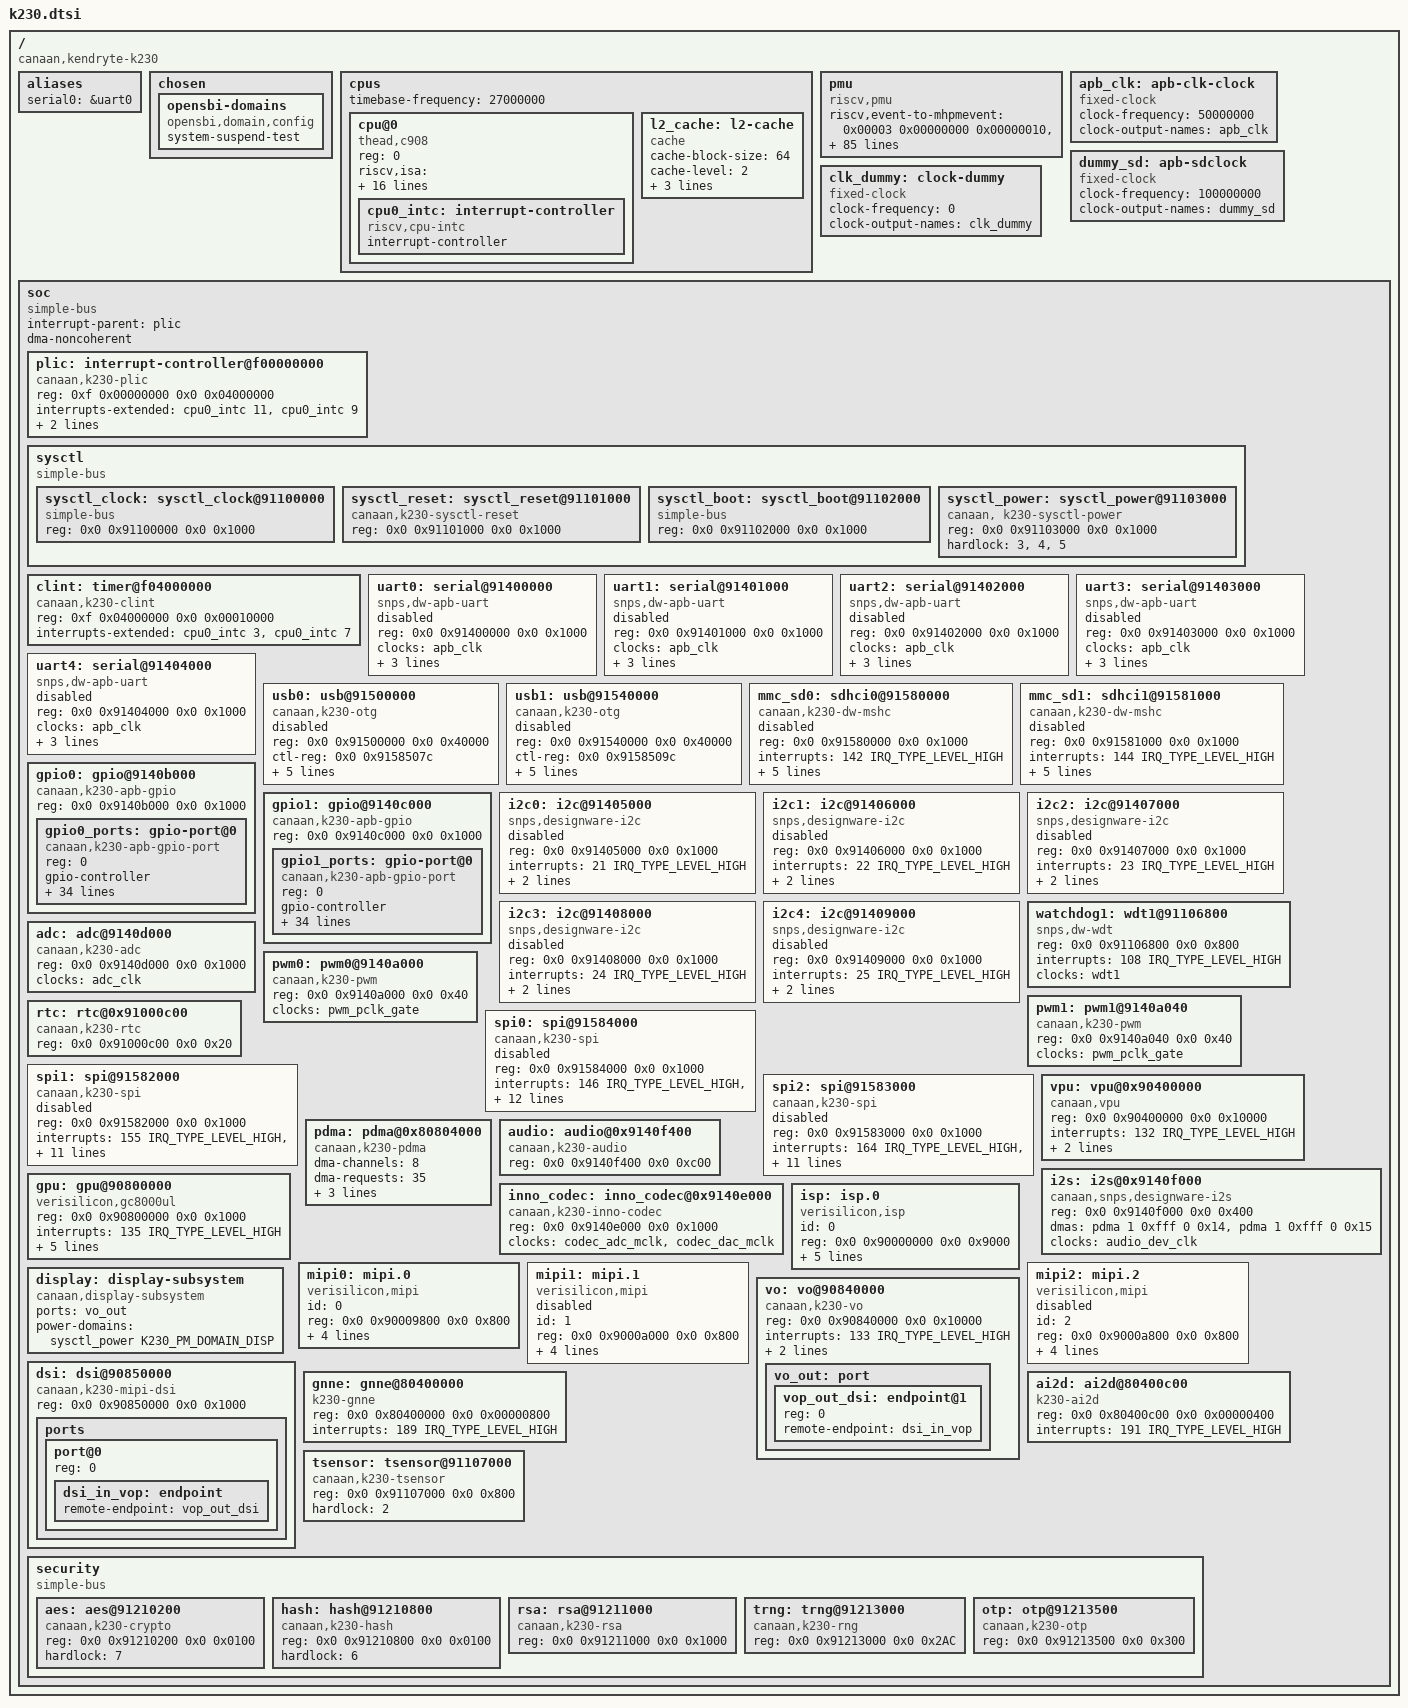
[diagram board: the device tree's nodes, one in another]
// SPDX-License-Identifier: GPL-2.0 OR MIT
/*
 * Copyright (C) 2024 Yangyu Chen <cyy@cyyself.name>
 */

#include <dt-bindings/interrupt-controller/irq.h>
#include <dt-bindings/soc/canaan,k230_pm_domains.h>
#include <dt-bindings/reset/canaan-k230-reset.h>
#include <dt-bindings/gpio/gpio.h>

/dts-v1/;
/ {
	#address-cells = <2>;
	#size-cells = <2>;
	compatible = "canaan,kendryte-k230";

	aliases {
		serial0 = &uart0;
	};

	chosen {
		opensbi-domains {
			compatible = "opensbi,domain,config";
			system-suspend-test;
		};
	};

	cpus {
		#address-cells = <1>;
		#size-cells = <0>;
		timebase-frequency = <27000000>;

		cpu@0 {
			compatible = "thead,c908", "riscv";
			device_type = "cpu";
			reg = <0>;
			riscv,isa = "rv64imafdcv_zba_zbb_zbc_zbs_zicbom_zicbop_zicboz_svpbmt";
			riscv,isa-base = "rv64i";
			riscv,isa-extensions = "i", "m", "a", "f", "d", "c", "v", "zba", "zbb",
					       "zbc", "zbs", "zicbom", "zicbop", "zicboz",
					       "zicntr", "zicsr", "zifencei", "zihpm", "svpbmt";
			riscv,cbom-block-size = <64>;
			riscv,cbop-block-size = <64>;
			riscv,cboz-block-size = <64>;
			d-cache-block-size = <64>;
			d-cache-sets = <128>;
			d-cache-size = <32768>;
			i-cache-block-size = <64>;
			i-cache-sets = <128>;
			i-cache-size = <32768>;
			next-level-cache = <&l2_cache>;
			mmu-type = "riscv,sv39";

			cpu0_intc: interrupt-controller {
				compatible = "riscv,cpu-intc";
				interrupt-controller;
				#interrupt-cells = <1>;
			};
		};

		l2_cache: l2-cache {
			compatible = "cache";
			cache-block-size = <64>;
			cache-level = <2>;
			cache-size = <262144>;
			cache-sets = <256>;
			cache-unified;
		};
	};

	pmu {
		compatible = "riscv,pmu";
		riscv,event-to-mhpmevent =
			/* PMU_HW_CACHE_REFERENCES -> ll_cache_read_access */
			<0x00003 0x00000000 0x00000010>,
			/* PMU_HW_CACHE_MISSES -> ll_cache_read_miss */
			<0x00004 0x00000000 0x00000011>,
			/* PMU_HW_BRANCH_INSTRUCTIONS -> inst_branch */
			<0x00005 0x00000000 0x00000007>,
			/* PMU_HW_BRANCH_MISSES -> inst_branch_mispredict */
			<0x00006 0x00000000 0x00000006>,
			/* PMU_HW_STALLED_CYCLES_FRONTEND -> ifu_stalled_cycle */
			<0x00008 0x00000000 0x00000027>,
			/* PMU_HW_STALLED_CYCLES_BACKEND -> idu_stalled_cycle */
			<0x00009 0x00000000 0x00000028>,
			/* L1D_READ_ACCESS -> l1_dcache_read_access */
			<0x10000 0x00000000 0x0000000c>,
			/* L1D_READ_MISS -> l1_dcache_read_miss */
			<0x10001 0x00000000 0x0000000d>,
			/* L1D_WRITE_ACCESS -> l1_dcache_write_access */
			<0x10002 0x00000000 0x0000000e>,
			/* L1D_WRITE_MISS -> l1_dcache_write_miss */
			<0x10003 0x00000000 0x0000000f>,
			/* L1I_READ_ACCESS -> l1_icache_access */
			<0x10008 0x00000000 0x00000001>,
			/* L1I_READ_MISS -> l1_icache_miss */
			<0x10009 0x00000000 0x00000002>,
			/* LL_READ_ACCESS -> ll_cache_read_access */
			<0x10010 0x00000000 0x00000010>,
			/* LL_READ_MISS -> ll_cache_read_miss */
			<0x10011 0x00000000 0x00000011>,
			/* LL_WRITE_ACCESS -> ll_cache_write_access */
			<0x10012 0x00000000 0x00000012>,
			/* LL_WRITE_MISS -> ll_cache_write_miss */
			<0x10013 0x00000000 0x00000013>,
			/* DTLB_READ_MISS -> dtlb_miss */
			<0x10019 0x00000000 0x00000004>,
			/* ITLB_READ_MISS -> itlb_miss */
			<0x10021 0x00000000 0x00000003>,
			/* BPU_READ_ACCESS -> branch_direction_prediction */
			<0x10030 0x00000000 0x0000001c>,
			/* BPU_READ_MISS -> branch_direction_misprediction */
			<0x10031 0x00000000 0x0000001b>;
		riscv,event-to-mhpmcounters =
			<0x00003 0x00003 0xfffffff8>,
			<0x00004 0x00004 0xfffffff8>,
			<0x00005 0x00005 0xfffffff8>,
			<0x00006 0x00006 0xfffffff8>,
			<0x00007 0x00007 0xfffffff8>,
			<0x00008 0x00008 0xfffffff8>,
			<0x00009 0x00009 0xfffffff8>,
			<0x0000a 0x0000a 0xfffffff8>,
			<0x10000 0x10000 0xfffffff8>,
			<0x10001 0x10001 0xfffffff8>,
			<0x10002 0x10002 0xfffffff8>,
			<0x10003 0x10003 0xfffffff8>,
			<0x10008 0x10008 0xfffffff8>,
			<0x10009 0x10009 0xfffffff8>,
			<0x10010 0x10010 0xfffffff8>,
			<0x10011 0x10011 0xfffffff8>,
			<0x10012 0x10012 0xfffffff8>,
			<0x10013 0x10013 0xfffffff8>,
			<0x10019 0x10019 0xfffffff8>,
			<0x10021 0x10021 0xfffffff8>,
			<0x10030 0x10030 0xfffffff8>,
			<0x10031 0x10031 0xfffffff8>;
		riscv,raw-event-to-mhpmcounters =
			<0x00000000 0x00000001 0xffffffff 0xffffffff 0xfffffff8>,
			<0x00000000 0x00000002 0xffffffff 0xffffffff 0xfffffff8>,
			<0x00000000 0x00000003 0xffffffff 0xffffffff 0xfffffff8>,
			<0x00000000 0x00000004 0xffffffff 0xffffffff 0xfffffff8>,
			<0x00000000 0x00000005 0xffffffff 0xffffffff 0xfffffff8>,
			<0x00000000 0x00000006 0xffffffff 0xffffffff 0xfffffff8>,
			<0x00000000 0x00000007 0xffffffff 0xffffffff 0xfffffff8>,
			<0x00000000 0x00000008 0xffffffff 0xffffffff 0xfffffff8>,
			<0x00000000 0x00000009 0xffffffff 0xffffffff 0xfffffff8>,
			<0x00000000 0x0000000a 0xffffffff 0xffffffff 0xfffffff8>,
			<0x00000000 0x0000000b 0xffffffff 0xffffffff 0xfffffff8>,
			<0x00000000 0x0000000c 0xffffffff 0xffffffff 0xfffffff8>,
			<0x00000000 0x0000000d 0xffffffff 0xffffffff 0xfffffff8>,
			<0x00000000 0x0000000e 0xffffffff 0xffffffff 0xfffffff8>,
			<0x00000000 0x0000000f 0xffffffff 0xffffffff 0xfffffff8>,
			<0x00000000 0x00000010 0xffffffff 0xffffffff 0xfffffff8>,
			<0x00000000 0x00000011 0xffffffff 0xffffffff 0xfffffff8>,
			<0x00000000 0x00000012 0xffffffff 0xffffffff 0xfffffff8>,
			<0x00000000 0x00000013 0xffffffff 0xffffffff 0xfffffff8>,
			<0x00000000 0x00000014 0xffffffff 0xffffffff 0xfffffff8>,
			<0x00000000 0x00000015 0xffffffff 0xffffffff 0xfffffff8>,
			<0x00000000 0x00000016 0xffffffff 0xffffffff 0xfffffff8>,
			<0x00000000 0x00000017 0xffffffff 0xffffffff 0xfffffff8>,
			<0x00000000 0x00000018 0xffffffff 0xffffffff 0xfffffff8>,
			<0x00000000 0x00000019 0xffffffff 0xffffffff 0xfffffff8>,
			<0x00000000 0x0000001a 0xffffffff 0xffffffff 0xfffffff8>,
			<0x00000000 0x0000001b 0xffffffff 0xffffffff 0xfffffff8>,
			<0x00000000 0x0000001c 0xffffffff 0xffffffff 0xfffffff8>,
			<0x00000000 0x0000001d 0xffffffff 0xffffffff 0xfffffff8>,
			<0x00000000 0x0000001e 0xffffffff 0xffffffff 0xfffffff8>,
			<0x00000000 0x0000001f 0xffffffff 0xffffffff 0xfffffff8>,
			<0x00000000 0x00000020 0xffffffff 0xffffffff 0xfffffff8>,
			<0x00000000 0x00000021 0xffffffff 0xffffffff 0xfffffff8>,
			<0x00000000 0x00000022 0xffffffff 0xffffffff 0xfffffff8>,
			<0x00000000 0x00000023 0xffffffff 0xffffffff 0xfffffff8>,
			<0x00000000 0x00000024 0xffffffff 0xffffffff 0xfffffff8>,
			<0x00000000 0x00000025 0xffffffff 0xffffffff 0xfffffff8>,
			<0x00000000 0x00000026 0xffffffff 0xffffffff 0xfffffff8>,
			<0x00000000 0x00000027 0xffffffff 0xffffffff 0xfffffff8>,
			<0x00000000 0x00000028 0xffffffff 0xffffffff 0xfffffff8>,
			<0x00000000 0x00000029 0xffffffff 0xffffffff 0xfffffff8>,
			<0x00000000 0x0000002a 0xffffffff 0xffffffff 0xfffffff8>;
	};

	apb_clk: apb-clk-clock {
		compatible = "fixed-clock";
		clock-frequency = <50000000>;
		clock-output-names = "apb_clk";
		#clock-cells = <0>;
	};
	dummy_sd:apb-sdclock {
		compatible = "fixed-clock";
		clock-frequency = <100000000>;
		clock-output-names = "dummy_sd";
		#clock-cells = <0x00>;
	};

	clk_dummy: clock-dummy {
		compatible = "fixed-clock";
		clock-frequency = <0>;
		clock-output-names = "clk_dummy";
		#clock-cells = <0>;
	};

	soc {
		compatible = "simple-bus";
		interrupt-parent = <&plic>;
		#address-cells = <2>;
		#size-cells = <2>;
		dma-noncoherent;
		ranges;

		plic: interrupt-controller@f00000000 {
			compatible = "canaan,k230-plic" ,"thead,c900-plic";
			reg = <0xf 0x00000000 0x0 0x04000000>;
			interrupts-extended = <&cpu0_intc 11>, <&cpu0_intc 9>;
			interrupt-controller;
			#address-cells = <0>;
			#interrupt-cells = <2>;
			riscv,ndev = <208>;
		};

		sysctl: sysctl {
			status					= "okay";
			#address-cells			= <2>;
			#size-cells				= <2>;
			compatible				= "simple-bus";
			ranges;

			sysctl_clock: sysctl_clock@91100000 {
				status              = "okay";
				compatible			= "simple-bus";
				reg                 = <0x0 0x91100000 0x0 0x1000>;
			};
			sysctl_reset: sysctl_reset@91101000 {
				status              = "okay";
				reg                 = <0x0 0x91101000 0x0 0x1000>;
				compatible      = "canaan,k230-sysctl-reset";
				#reset-cells    = <4>;
				/* indicate consumer resets have 5 parameters.
				 * phandle+offset+type+done+assert
				 */
			};
			sysctl_boot: sysctl_boot@91102000 {
				status              = "okay";
				compatible			= "simple-bus";
				reg                 = <0x0 0x91102000 0x0 0x1000>;
			};
			sysctl_power: sysctl_power@91103000 {
				status              = "okay";
				reg                 = <0x0 0x91103000 0x0 0x1000>;
				compatible          = "canaan, k230-sysctl-power";
				hardlock            = <3>, <4>, <5>;
				#power-domain-cells = <1>;  /* more than 1 power provider */
			};
		};

		clint: timer@f04000000 {
			compatible = "canaan,k230-clint", "thead,c900-clint";
			reg = <0xf 0x04000000 0x0 0x00010000>;
			interrupts-extended = <&cpu0_intc 3>, <&cpu0_intc 7>;
		};

		uart0: serial@91400000 {
			compatible = "snps,dw-apb-uart";
			reg = <0x0 0x91400000 0x0 0x1000>;
			clocks = <&apb_clk>;
			interrupts = <16 IRQ_TYPE_LEVEL_HIGH>;
			reg-io-width = <4>;
			reg-shift = <2>;
			status = "disabled";
		};

		uart1: serial@91401000 {
			compatible = "snps,dw-apb-uart";
			reg = <0x0 0x91401000 0x0 0x1000>;
			clocks = <&apb_clk>;
			interrupts = <17 IRQ_TYPE_LEVEL_HIGH>;
			reg-io-width = <4>;
			reg-shift = <2>;
			status = "disabled";
		};

		uart2: serial@91402000 {
			compatible = "snps,dw-apb-uart";
			reg = <0x0 0x91402000 0x0 0x1000>;
			clocks = <&apb_clk>;
			interrupts = <18 IRQ_TYPE_LEVEL_HIGH>;
			reg-io-width = <4>;
			reg-shift = <2>;
			status = "disabled";
		};

		uart3: serial@91403000 {
			compatible = "snps,dw-apb-uart";
			reg = <0x0 0x91403000 0x0 0x1000>;
			clocks = <&apb_clk>;
			interrupts = <19 IRQ_TYPE_LEVEL_HIGH>;
			reg-io-width = <4>;
			reg-shift = <2>;
			status = "disabled";
		};

		uart4: serial@91404000 {
			compatible = "snps,dw-apb-uart";
			reg = <0x0 0x91404000 0x0 0x1000>;
			clocks = <&apb_clk>;
			interrupts = <20 IRQ_TYPE_LEVEL_HIGH>;
			reg-io-width = <4>;
			reg-shift = <2>;
			status = "disabled";
		};

		usb0: usb@91500000 {
			compatible = "canaan,k230-otg";
			reg = <0x0 0x91500000 0x0 0x40000>;
			ctl-reg = <0x0 0x9158507c>;
			interrupts = <173 IRQ_TYPE_LEVEL_HIGH>;
			clocks = <&clk_dummy>;
			clock-names = "otg";
			g-rx-fifo-size = <512>;
			g-np-tx-fifo-size = <64>;
			g-tx-fifo-size = <512 1024 64 64 64 64>;
			status = "disabled";
		};

		usb1: usb@91540000 {
			compatible = "canaan,k230-otg";
			reg = <0x0 0x91540000 0x0 0x40000>;
			ctl-reg = <0x0 0x9158509c>;
			interrupts = <174 IRQ_TYPE_LEVEL_HIGH>;
			clocks = <&clk_dummy>;
			clock-names = "otg";
			g-rx-fifo-size = <512>;
			g-np-tx-fifo-size = <64>;
			g-tx-fifo-size = <512 1024 64 64 64 64>;
			status = "disabled";
		};
		mmc_sd0: sdhci0@91580000 {
			compatible = "canaan,k230-dw-mshc";
			reg = <0x0 0x91580000 0x0 0x1000>;
			interrupts = <142 IRQ_TYPE_LEVEL_HIGH>;
			interrupt-names = "sdhci0irq";
			clocks = <&dummy_sd>,<&dummy_sd>;
			clock-names = "core", "bus";
			max-frequency = <200000000>;
			bus-width = <8>;
			sdhci,auto-cmd12;
			dma-noncoherent;
			status = "disabled";
		};

		mmc_sd1: sdhci1@91581000 {
			compatible = "canaan,k230-dw-mshc";
			reg = <0x0 0x91581000 0x0 0x1000>;
			interrupts = <144 IRQ_TYPE_LEVEL_HIGH>;
			interrupt-names = "sdhci1irq";
			clocks = <&dummy_sd>,<&dummy_sd>;
			clock-names = "core", "bus";
			max-frequency = <50000000>;
			bus-width = <4>;
			sdhci,auto-cmd12;
			dma-noncoherent;
			//status = "disabled";/*disabled, okay*/
			status = "disabled";
		};

		gpio0: gpio@9140b000 {
			compatible = "canaan,k230-apb-gpio";
			reg = <0x0 0x9140b000 0x0 0x1000>;
			#address-cells = <1>;
			#size-cells = <0>;

			gpio0_ports: gpio-port@0 {
				compatible = "canaan,k230-apb-gpio-port";
				reg = <0>;
				gpio-controller;
				#gpio-cells = <2>;
				snps,nr-gpios = <32>;
				interrupt-controller;
				#interrupt-cells = <2>;
				interrupts =
					<32 IRQ_TYPE_EDGE_RISING>,
					<33 IRQ_TYPE_EDGE_RISING>,
					<34 IRQ_TYPE_EDGE_RISING>,
					<35 IRQ_TYPE_EDGE_RISING>,
					<36 IRQ_TYPE_EDGE_RISING>,
					<37 IRQ_TYPE_EDGE_RISING>,
					<38 IRQ_TYPE_EDGE_RISING>,
					<39 IRQ_TYPE_EDGE_RISING>,
					<40 IRQ_TYPE_EDGE_RISING>,
					<41 IRQ_TYPE_EDGE_RISING>,
					<42 IRQ_TYPE_EDGE_RISING>,
					<43 IRQ_TYPE_EDGE_RISING>,
					<44 IRQ_TYPE_EDGE_RISING>,
					<45 IRQ_TYPE_EDGE_RISING>,
					<46 IRQ_TYPE_EDGE_RISING>,
					<47 IRQ_TYPE_EDGE_RISING>,
					<48 IRQ_TYPE_EDGE_RISING>,
					<49 IRQ_TYPE_EDGE_RISING>,
					<50 IRQ_TYPE_EDGE_RISING>,
					<51 IRQ_TYPE_EDGE_RISING>,
					<52 IRQ_TYPE_EDGE_RISING>,
					<53 IRQ_TYPE_EDGE_RISING>,
					<54 IRQ_TYPE_EDGE_RISING>,
					<55 IRQ_TYPE_EDGE_RISING>,
					<56 IRQ_TYPE_EDGE_RISING>,
					<57 IRQ_TYPE_EDGE_RISING>,
					<58 IRQ_TYPE_EDGE_RISING>,
					<59 IRQ_TYPE_EDGE_RISING>,
					<60 IRQ_TYPE_EDGE_RISING>,
					<61 IRQ_TYPE_EDGE_RISING>,
					<62 IRQ_TYPE_EDGE_RISING>,
					<63 IRQ_TYPE_EDGE_RISING>;
			};
		};

		gpio1: gpio@9140c000 {
			compatible = "canaan,k230-apb-gpio";
			reg = <0x0 0x9140c000 0x0 0x1000>;
			#address-cells = <1>;
			#size-cells = <0>;

			gpio1_ports: gpio-port@0 {
				compatible = "canaan,k230-apb-gpio-port";
				reg = <0>;
				gpio-controller;
				#gpio-cells = <2>;
				snps,nr-gpios = <32>;
				interrupt-controller;
				#interrupt-cells = <2>;
				interrupts =
					<64 IRQ_TYPE_EDGE_RISING>,
					<65 IRQ_TYPE_EDGE_RISING>,
					<66 IRQ_TYPE_EDGE_RISING>,
					<67 IRQ_TYPE_EDGE_RISING>,
					<68 IRQ_TYPE_EDGE_RISING>,
					<69 IRQ_TYPE_EDGE_RISING>,
					<70 IRQ_TYPE_EDGE_RISING>,
					<71 IRQ_TYPE_EDGE_RISING>,
					<72 IRQ_TYPE_EDGE_RISING>,
					<73 IRQ_TYPE_EDGE_RISING>,
					<74 IRQ_TYPE_EDGE_RISING>,
					<75 IRQ_TYPE_EDGE_RISING>,
					<76 IRQ_TYPE_EDGE_RISING>,
					<77 IRQ_TYPE_EDGE_RISING>,
					<78 IRQ_TYPE_EDGE_RISING>,
					<79 IRQ_TYPE_EDGE_RISING>,
					<80 IRQ_TYPE_EDGE_RISING>,
					<81 IRQ_TYPE_EDGE_RISING>,
					<82 IRQ_TYPE_EDGE_RISING>,
					<83 IRQ_TYPE_EDGE_RISING>,
					<84 IRQ_TYPE_EDGE_RISING>,
					<85 IRQ_TYPE_EDGE_RISING>,
					<86 IRQ_TYPE_EDGE_RISING>,
					<87 IRQ_TYPE_EDGE_RISING>,
					<88 IRQ_TYPE_EDGE_RISING>,
					<89 IRQ_TYPE_EDGE_RISING>,
					<90 IRQ_TYPE_EDGE_RISING>,
					<91 IRQ_TYPE_EDGE_RISING>,
					<92 IRQ_TYPE_EDGE_RISING>,
					<93 IRQ_TYPE_EDGE_RISING>,
					<94 IRQ_TYPE_EDGE_RISING>,
					<95 IRQ_TYPE_EDGE_RISING>;
			};
		};

		i2c0: i2c@91405000 {
			#address-cells = <1>;
			#size-cells = <0>;
			compatible = "snps,designware-i2c";
			reg = <0x0 0x91405000 0x0 0x1000>;
			interrupts = <21 IRQ_TYPE_LEVEL_HIGH>;
			clocks = <&i2c0_clk>;
			clock-frequency = <100000>;
			status = "disabled";
		};

		i2c1: i2c@91406000 {
			#address-cells = <1>;
			#size-cells = <0>;
			compatible = "snps,designware-i2c";
			reg = <0x0 0x91406000 0x0 0x1000>;
			interrupts = <22 IRQ_TYPE_LEVEL_HIGH>;
			clocks = <&i2c1_clk>;
			clock-frequency = <400000>;
			status = "disabled";
		};

		i2c2: i2c@91407000 {
			#address-cells = <1>;
			#size-cells = <0>;
			compatible = "snps,designware-i2c";
			reg = <0x0 0x91407000 0x0 0x1000>;
			interrupts = <23 IRQ_TYPE_LEVEL_HIGH>;
			clocks = <&i2c2_clk>;
			clock-frequency = <400000>;
			status = "disabled";
		};

		i2c3: i2c@91408000 {
			#address-cells = <1>;
			#size-cells = <0>;
			compatible = "snps,designware-i2c";
			reg = <0x0 0x91408000 0x0 0x1000>;
			interrupts = <24 IRQ_TYPE_LEVEL_HIGH>;
			clocks = <&i2c3_clk>;
			clock-frequency = <400000>;
			status = "disabled";
		};

		i2c4: i2c@91409000 {
			#address-cells = <1>;
			#size-cells = <0>;
			compatible = "snps,designware-i2c";
			reg = <0x0 0x91409000 0x0 0x1000>;
			interrupts = <25 IRQ_TYPE_LEVEL_HIGH>;
			clocks = <&i2c4_clk>;
			clock-frequency = <400000>;
			status = "disabled";
		};

		watchdog1: wdt1@91106800 {
			compatible = "snps,dw-wdt";
			reg = <0x0 0x91106800 0x0 0x800>;
			interrupts = <108 IRQ_TYPE_LEVEL_HIGH>;
			clocks = <&wdt1>;
		};

		adc: adc@9140d000 {
			compatible = "canaan,k230-adc";
			reg = <0x0 0x9140d000 0x0 0x1000>;
			clocks = <&adc_clk>;
		};

		pwm0: pwm0@9140a000 {
			compatible = "canaan,k230-pwm";
			reg = <0x0 0x9140a000 0x0 0x40>;
			clocks = <&pwm_pclk_gate>;
		};

		pwm1: pwm1@9140a040 {
			compatible = "canaan,k230-pwm";
			reg = <0x0 0x9140a040 0x0 0x40>;
			clocks = <&pwm_pclk_gate>;
		};

		rtc: rtc@0x91000c00 {
			compatible = "canaan,k230-rtc";
			reg = <0x0 0x91000c00 0x0 0x20>;
		};

		spi0: spi@91584000 {
			compatible = "canaan,k230-spi";
			reg = <0x0 0x91584000 0x0 0x1000>;
			#address-cells = <1>;
			#size-cells = <0>;
			interrupts = <146 IRQ_TYPE_LEVEL_HIGH>,
				     <147 IRQ_TYPE_LEVEL_HIGH>,
				     <148 IRQ_TYPE_LEVEL_HIGH>,
				     <149 IRQ_TYPE_LEVEL_HIGH>,
				     <150 IRQ_TYPE_LEVEL_HIGH>,
				     <151 IRQ_TYPE_LEVEL_HIGH>,
				     <152 IRQ_TYPE_LEVEL_HIGH>,
				     <153 IRQ_TYPE_LEVEL_HIGH>,
				     <154 IRQ_TYPE_LEVEL_HIGH>;
			rx-sample-delay-ns = <5>;
			num-cs = <1>;
			reg-io-width = <4>;
			clocks = <&ssi0_clk>;
			status = "disabled";
		};

		spi1: spi@91582000 {
			compatible = "canaan,k230-spi";
			reg = <0x0 0x91582000 0x0 0x1000>;
			#address-cells = <1>;
			#size-cells = <0>;
			interrupts = <155 IRQ_TYPE_LEVEL_HIGH>,
				     <156 IRQ_TYPE_LEVEL_HIGH>,
				     <157 IRQ_TYPE_LEVEL_HIGH>,
				     <158 IRQ_TYPE_LEVEL_HIGH>,
				     <159 IRQ_TYPE_LEVEL_HIGH>,
				     <160 IRQ_TYPE_LEVEL_HIGH>,
				     <161 IRQ_TYPE_LEVEL_HIGH>,
				     <162 IRQ_TYPE_LEVEL_HIGH>,
				     <163 IRQ_TYPE_LEVEL_HIGH>;
			num-cs = <1>;
			reg-io-width = <4>;
			clocks = <&ssi1_clk>;
			status = "disabled";
		};

		spi2: spi@91583000 {
			compatible = "canaan,k230-spi";
			reg = <0x0 0x91583000 0x0 0x1000>;
			#address-cells = <1>;
			#size-cells = <0>;
			interrupts = <164 IRQ_TYPE_LEVEL_HIGH>,
				     <165 IRQ_TYPE_LEVEL_HIGH>,
				     <166 IRQ_TYPE_LEVEL_HIGH>,
				     <167 IRQ_TYPE_LEVEL_HIGH>,
				     <168 IRQ_TYPE_LEVEL_HIGH>,
				     <169 IRQ_TYPE_LEVEL_HIGH>,
				     <170 IRQ_TYPE_LEVEL_HIGH>,
				     <171 IRQ_TYPE_LEVEL_HIGH>,
				     <172 IRQ_TYPE_LEVEL_HIGH>;
			num-cs = <1>;
			reg-io-width = <4>;
			clocks = <&ssi2_clk>;
			status = "disabled";
		};

		vpu: vpu@0x90400000 {
			status              = "okay";
			compatible          = "canaan,vpu";
			reg                 = <0x0 0x90400000 0x0 0x10000>;
			interrupts          = <132 IRQ_TYPE_LEVEL_HIGH>;
			power-domains       = <&sysctl_power K230_PM_DOMAIN_VPU>;
			clocks              = <&vpu_src>;
			clock-names         = "vpu";
		};

		pdma: pdma@0x80804000 {
			#dma-cells          = <4>;
			dma-channels        = <8>;
			dma-requests        = <35>;
			status              = "okay";
			compatible          = "canaan,k230-pdma";
			reg                 = <0x0  0x80804000 0x0 0x400>;
			interrupts          = <203 IRQ_TYPE_LEVEL_HIGH>;
			clocks              = <&pdma_aclk_gate>;
		};

		i2s: i2s@0x9140f000 {
			status              = "okay";
			compatible          = "canaan,snps,designware-i2s";
			// compatible          = "snps,designware-i2s";
			reg                 = <0x0 0x9140f000 0x0 0x400>;
			dmas                = <&pdma 1 0xfff 0 0x14>, <&pdma 1 0xfff 0 0x15>;
			dma-names           = "tx", "rx";
			clocks              = <&audio_dev_clk>;
			clock-names         = "i2sclk";
		};

		/* audio */
		audio: audio@0x9140f400 {
			status              = "okay";
			compatible          = "canaan,k230-audio";
			reg                 = <0x0 0x9140f400 0x0 0xc00>;
		};

		inno_codec:inno_codec@0x9140e000{
			status              = "okay";
			compatible          = "canaan,k230-inno-codec";
			reg                 = <0x0 0x9140e000 0x0 0x1000>;
			clocks              = <&codec_adc_mclk>,<&codec_dac_mclk>;
			clock-names         = "adc", "dac";
		};

		gpu: gpu@90800000 {
			compatible = "verisilicon,gc8000ul";
			reg = <0x0 0x90800000 0x0 0x1000>;
			interrupts = <135 IRQ_TYPE_LEVEL_HIGH>;
			power-domains = <&sysctl_power K230_PM_DOMAIN_DISP>;
			resets = <
				&sysctl_reset
				K230_RESET_V2P5D_REG_OFFSET
				K230_RESET_V2P5D_TYPE
				K230_RESET_V2P5D_DONE_BIT
				K230_RESET_V2P5D_ASSERT_BIT
			>;
			reset-names = "vglite";
			clocks = <&disp_gpu>;
			clock-names = "vglite";
			status = "okay";
		};

		isp: isp.0 {
			compatible = "verisilicon,isp";
			id = <0>;
			reg = <0x0 0x90000000 0x0 0x9000>;
			interrupts = <129 IRQ_TYPE_LEVEL_HIGH>,
						 <127 IRQ_TYPE_LEVEL_HIGH>,
						 <128 IRQ_TYPE_LEVEL_HIGH>;
			resets = <&sysctl_reset
					  K230_RESET_ISP_REG_OFFSET
					  K230_RESET_ISP_TYPE
					  K230_RESET_ISP_DONE_BIT
					  K230_RESET_ISP_ASSERT_BIT>;
			reset-names = "isp";
			status = "okay";
		};

		mipi0: mipi.0 {
			compatible = "verisilicon,mipi";
			id = <0>;
			reg = <0x0 0x90009800 0x0 0x800>;
			interrupts = <115 IRQ_TYPE_LEVEL_HIGH>;
			resets = <&sysctl_reset
					  K230_RESET_CSI0_REG_OFFSET
					  K230_RESET_CSI0_TYPE
					  K230_RESET_CSI0_DONE_BIT
					  K230_RESET_CSI0_ASSERT_BIT>,
					 <&sysctl_reset
					  K230_RESET_M0_REG_OFFSET
					  K230_RESET_M0_TYPE
					  K230_RESET_M0_DONE_BIT
					  K230_RESET_M0_ASSERT_BIT>;
			reset-names = "csi", "sensor";
			status = "okay";
		};

		mipi1: mipi.1 {
			compatible = "verisilicon,mipi";
			id = <1>;
			reg = <0x0 0x9000a000 0x0 0x800>;
			interrupts = <118 IRQ_TYPE_LEVEL_HIGH>;
			resets = <&sysctl_reset
					  K230_RESET_CSI1_REG_OFFSET
					  K230_RESET_CSI1_TYPE
					  K230_RESET_CSI1_DONE_BIT
					  K230_RESET_CSI1_ASSERT_BIT>,
					 <&sysctl_reset
					  K230_RESET_M1_REG_OFFSET
					  K230_RESET_M1_TYPE
					  K230_RESET_M1_DONE_BIT
					  K230_RESET_M1_ASSERT_BIT>;
			reset-names = "csi", "sensor";
			status = "disabled";
		};

		mipi2: mipi.2 {
			compatible = "verisilicon,mipi";
			id = <2>;
			reg = <0x0 0x9000a800 0x0 0x800>;
			interrupts = <121 IRQ_TYPE_LEVEL_HIGH>;
			resets = <&sysctl_reset
					  K230_RESET_CSI2_REG_OFFSET
					  K230_RESET_CSI2_TYPE
					  K230_RESET_CSI2_DONE_BIT
					  K230_RESET_CSI2_ASSERT_BIT>,
					 <&sysctl_reset
					  K230_RESET_M2_REG_OFFSET
					  K230_RESET_M2_TYPE
					  K230_RESET_M2_DONE_BIT
					  K230_RESET_M2_ASSERT_BIT>;
			reset-names = "csi", "sensor";
			status = "disabled";
		};

		display: display-subsystem {
			compatible = "canaan,display-subsystem";
			ports = <&vo_out>;
			status = "okay";
			power-domains = <&sysctl_power K230_PM_DOMAIN_DISP>;
		};

		vo: vo@90840000 {
			compatible = "canaan,k230-vo";
			reg = <0x0 0x90840000 0x0 0x10000>;
			interrupts = <133 IRQ_TYPE_LEVEL_HIGH>;
			status = "okay";

			background = <0xffffff>;
			vth_line = <10>;

			vo_out: port {
				#address-cells = <1>;
				#size-cells = <0>;
				vop_out_dsi: endpoint@1 {
					reg = <0>;
					remote-endpoint = <&dsi_in_vop>;
				};
			};
		};

		dsi: dsi@90850000 {
			compatible = "canaan,k230-mipi-dsi";
			reg = <0x0 0x90850000 0x0 0x1000>;
			#address-cells = <1>;
			#size-cells = <0>;
			status = "okay";

			ports {
				#address-cells = <1>;
				#size-cells = <0>;

				port@0 {
					reg = <0>;
					dsi_in_vop: endpoint {
						remote-endpoint = <&vop_out_dsi>;
					};
				};
			};
		};

		gnne: gnne@80400000 {
			status = "okay";
			compatible = "k230-gnne";
			reg = <0x0 0x80400000 0x0 0x00000800>;
			interrupts = <189 IRQ_TYPE_LEVEL_HIGH>;
		};

		ai2d: ai2d@80400c00 {
			status = "okay";
			compatible = "k230-ai2d";
			reg = <0x0 0x80400c00 0x0 0x00000400>;
			interrupts = <191 IRQ_TYPE_LEVEL_HIGH>;
		};

		tsensor: tsensor@91107000 {
			status = "okay";
			compatible = "canaan,k230-tsensor";
			reg = <0x0 0x91107000 0x0 0x800>;
			hardlock = <2>;
		};

		security: security {
			status = "okay";
			compatible = "simple-bus";
			#address-cells = <2>;
			#size-cells = <2>;
			ranges;

			aes: aes@91210200 {
				status = "okay";
				compatible = "canaan,k230-crypto";
				reg	= <0x0 0x91210200 0x0 0x0100>;
				hardlock = <7>;
			};

			hash: hash@91210800 {
				status = "okay";
				compatible = "canaan,k230-hash";
				reg = <0x0 0x91210800 0x0 0x0100>;
				hardlock = <6>;
			};

			rsa: rsa@91211000 {
				status = "okay";
				compatible = "canaan,k230-rsa";
				reg	= <0x0 0x91211000 0x0 0x1000>;
			};

			trng: trng@91213000 {
				status = "okay";
				compatible = "canaan,k230-rng";
				reg = <0x0 0x91213000 0x0 0x2AC>;
			};

			otp: otp@91213500 {
				status = "okay";
				compatible = "canaan,k230-otp";
				reg = <0x0 0x91213500 0x0 0x300>;
			};
		};
	};
};
#include "k230_clock_provider.dtsi"
